# WKUP_CTRL_MMR0 register map
Vendor: Texas Instruments
Peripheral module from a debugger description file (folder J7ES).
Registers are 32-bit, access per field, reset 0x0 unless marked. A register's access mark holds for its fields unless they carry their own. Offsets are as the file gives them; lines under a group give offsets from that group; [hi:lo] are bit positions; {n}, {i} and the like mark numbered series; 'fields as' and 'values as' point back to an identical list; <NAME> marks a mode.

## WKUP_CTRL_MMR0
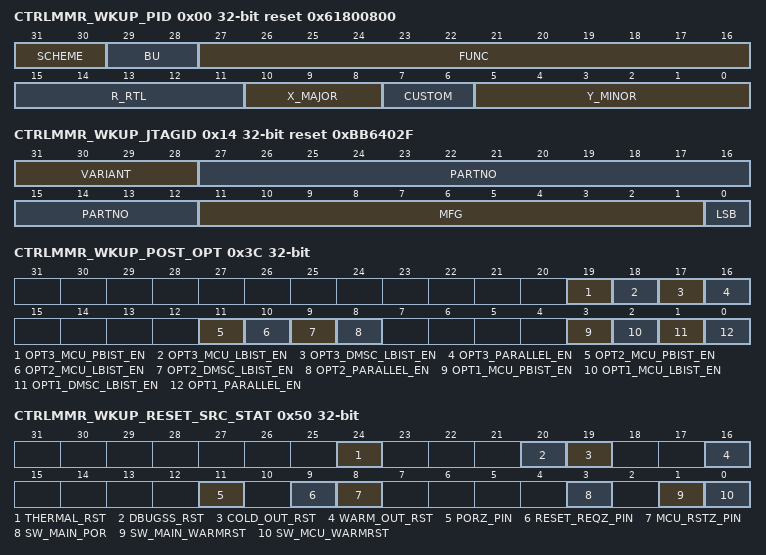
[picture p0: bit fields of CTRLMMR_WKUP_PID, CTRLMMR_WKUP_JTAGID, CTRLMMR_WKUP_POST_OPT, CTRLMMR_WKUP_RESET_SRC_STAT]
0x00 CTRLMMR_WKUP_PID ro reset 0x61800800 — Peripheral release details.
  [31:30] SCHEME
  [29:28] BU — Business unit
  [27:16] FUNC — Module functional identifier
  [15:11] R_RTL — RTL revision
  [10:8] X_MAJOR — Major revision
  [7:6] CUSTOM — Custom revision
  [5:0] Y_MINOR — Minor revision
0x08 CTRLMMR_WKUP_MMR_CFG1 ro reset 0x800000DF — Indicates the MMR configuration.
  [7:0] PARTITIONS — Indicates present partitions
0x14 CTRLMMR_WKUP_JTAGID ro reset 0xBB6402F — The register must be readable by the configuration bus so that this can be accessed via the JTAG and CPU. In Boundary Scan mode, this ID should also be readable with only TCLK present. This means without a valid CPU clock running and also implies that Fusefarm scan is not necessary. The Variant field should be set in the top metal mask so that this may be changed if a future PG is necessary. All other fields may be hard coded.
  [31:28] VARIANT — Used to indicate new PGs
  [27:12] PARTNO — Part number for boundary scan
  [11:1] MFG — Indicates manufacturer
  [0] LSB — Always 1
{0x20+4i} CTRLMMR_WKUP_DIE_ID{i} ro reset not defined (i=0..3) — Contains information to identify this particular die.
  [31:0] DIEID — Contains individual die information
0x30 CTRLMMR_WKUP_DEVSTAT (reset mask 0xFFFFFC00) — Indicates MCU bootstrap selection. The default value of this register is determined by the MCU bootstrap pins when the por_boot_cfg_srst_n input is de-asserted.
  [9:0] BOOTMODE rw — Indicates MCU bootstrap selection. The default value of this register is determined by the MCU bootstrap pins when the por_boot_cfg_srst_n input is de-asserted. However, this register can be written before a warm boot to invoke a different boot mode than that latched from the BOOTMODE pins.
0x34 CTRLMMR_WKUP_BOOTCFG ro (reset mask 0xFFFFFC00) — Indicates MCU bootstrap selection latched at power-on reset by PORz. The default value of this register is determined by the MCU bootstrap pins when the por_boot_cfg_srst_n input is de-asserted and will remain until the MCU bootstrap pins are re-latched on a subsequent por_boot_cfg_srst_n rising edge.
  [9:0] BOOTMODE — Indicates MCU boot mode as latched at power-on reset. These bits always contain the values latched.
0x38 CTRLMMR_WKUP_POST_SEL_STAT ro (reset mask 0xFFFFFFFC) — Indicates which power-on self test option was performed.
  [1:0] POST_SEL_STAT — Indicates which POST option was selected at power-up
0x3C CTRLMMR_WKUP_POST_OPT ro (reset mask 0xFFF0F0F0) — Indicates the 3 available power-on self test (POST) options: Bits 3:0 - POST Option 1 Bits 11:8 - POST Option 2 Bits 19:16 - POST Option 3
  [19] OPT3_MCU_PBIST_EN — MCU R5 PBIST enabled
  [18] OPT3_MCU_LBIST_EN — MCU R5 LBIST enabled
  [17] OPT3_DMSC_LBIST_EN — DMSC LBIST enabled
  [16] OPT3_PARALLEL_EN — Selects DMSC/MCU R5 LBIST sequencing
  [11] OPT2_MCU_PBIST_EN — MCU R5 PBIST enabled
  [10] OPT2_MCU_LBIST_EN — MCU R5 LBIST enabled
  [9] OPT2_DMSC_LBIST_EN — DMSC LBIST enabled
  [8] OPT2_PARALLEL_EN — Selects DMSC/MCU R5 LBIST sequencing
  [3] OPT1_MCU_PBIST_EN — MCU R5 PBIST enabled
  [2] OPT1_MCU_LBIST_EN — MCU R5 LBIST enabled
  [1] OPT1_DMSC_LBIST_EN — DMSC LBIST enabled
  [0] OPT1_PARALLEL_EN — Selects DMSC/MCU R5 LBIST sequencing
0x50 CTRLMMR_WKUP_RESET_SRC_STAT access not given — Indicates source of last device reset.
  [24] THERMAL_RST — When set, indicates that a VTM Max Temp Thermal reset occurred. (access REC)
  [20] DBUGSS_RST — When set, indicates that a Debug reset occurred. (access FEC)
  [19] COLD_OUT_RST — When set, indicates that a DMSC Cold reset occurred. (access FEC)
  [16] WARM_OUT_RST — When set, indicates that a DSMC Warm reset occured. (access FEC)
  [11] PORZ_PIN — When set indicates that a PORz pin reset occurred. (access FEC)
  [9] RESET_REQZ_PIN — When set indicates that a RESET_REQz pin reset occurred. (access FEC)
  [8] MCU_RSTZ_PIN — When set indicates that a MCU_RESETz pin reset occurred. (access FEC)
  [3] SW_MAIN_POR — When set, indicates that a Software MAIN Power-on reset occurred. (access FEC)
  [1] SW_MAIN_WARMRST — When set indicates that a Software MAIN Warm reset occurred. (access FEC)
  [0] SW_MCU_WARMRST — When set indicates that a Software MCU Warm reset occurred. (access FEC)
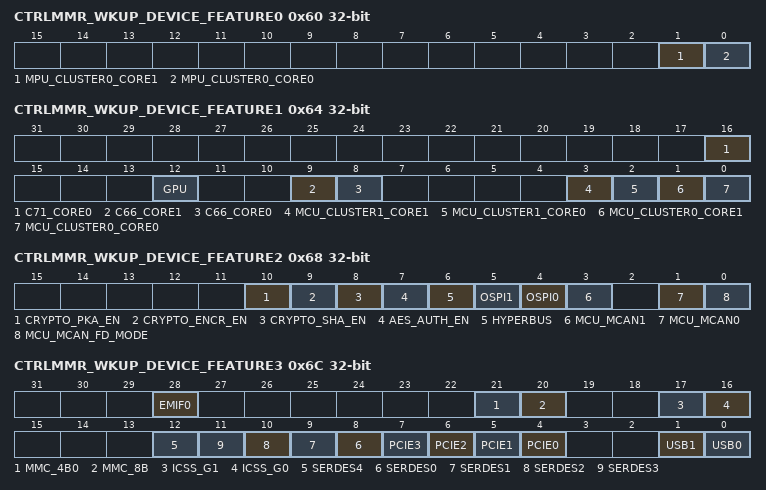
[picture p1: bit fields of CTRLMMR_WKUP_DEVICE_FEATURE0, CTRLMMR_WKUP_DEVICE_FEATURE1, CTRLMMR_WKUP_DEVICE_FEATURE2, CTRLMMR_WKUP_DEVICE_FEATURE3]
0x60 CTRLMMR_WKUP_DEVICE_FEATURE0 ro (reset mask 0xFFFFFFCC) — Indicates enabled MPU processing elements on the device.
  [1] MPU_CLUSTER0_CORE1 — MPU Cluster0 Core 1 is enabled when set
  [0] MPU_CLUSTER0_CORE0 — MPU Cluster0 Core 0 is enabled when set
0x64 CTRLMMR_WKUP_DEVICE_FEATURE1 ro (reset mask 0xFFFCECF0) — Indicates enabled non-MPU processing elements on the device.
  [16] C71_CORE0 — C71 Core0 is enabled when set
  [12] GPU — GPU is enabled when set
  [9] C66_CORE1 — C66 Core1 is enabled when set
  [8] C66_CORE0 — C66 Core0 is enabled when set
  [3] MCU_CLUSTER1_CORE1 — MAIN MCU Cluster1 Core1 is enabled when set
  [2] MCU_CLUSTER1_CORE0 — MAIN MCU Cluster1 Core0 is enabled when set
  [1] MCU_CLUSTER0_CORE1 — MAIN MCU Cluster0 Core1 is enabled when set
  [0] MCU_CLUSTER0_CORE0 — MAIN MCU Cluster0 Core0 is enabled when set
0x68 CTRLMMR_WKUP_DEVICE_FEATURE2 ro (reset mask 0xFFFFF804) — Indicates enabled MCU domain interface elements on the device.
  [10] CRYPTO_PKA_EN — MCU SA2_UL Crypto Module PKA enabled
  [9] CRYPTO_ENCR_EN — MCU SA2_UL Crypto Module AES/3DES/DBRG enabled
  [8] CRYPTO_SHA_EN — MCU SA2_UL Crypto Module SHA/MD5 enabled
  [7] AES_AUTH_EN — AES authentication is enabled in MCU_FlashSS and DMSC when set
  [6] HYPERBUS — MCU_FSS0_HPB0 is enabled when set
  [5] OSPI1 — MCU_OSPI1 is enabled when set
  [4] OSPI0 — MCU_OSPI0 is enabled when set
  [3] MCU_MCAN1 — MCU_MCAN1 is enabled when set
  [1] MCU_MCAN0 — MCU_MCAN0 is enabled when set
  [0] MCU_MCAN_FD_MODE — FD mode is supported on MCU_MCAN[1:0] when set
0x6C CTRLMMR_WKUP_DEVICE_FEATURE3 ro (reset mask 0xCF8CC008) — Indicates enabled MAIN domain interface elements on the device.
  [28] EMIF0 — EMIF0 is enabled when set
  [21] MMC_4B0 — 4-bit MMCSD1 is enabled when set
  [20] MMC_8B — 8-bit MMCSD0 is enabled when set
  [17] ICSS_G1 — ICSS_G1 is enabled when set
  [16] ICSS_G0 — ICSS_G0 is enabled when set
  [12] SERDES4 — 10G SERDES4 is enabled when set
  [n+8] SERDES{n} (n=0..3) — 16G SERDES{n} is enabled when set
  [n+4] PCIE{n} (n=0..3) — PCIe{n} is enabled when set
  [1] USB1 — USB1 is enabled when set
  [0] USB0 — USB0 is enabled when set
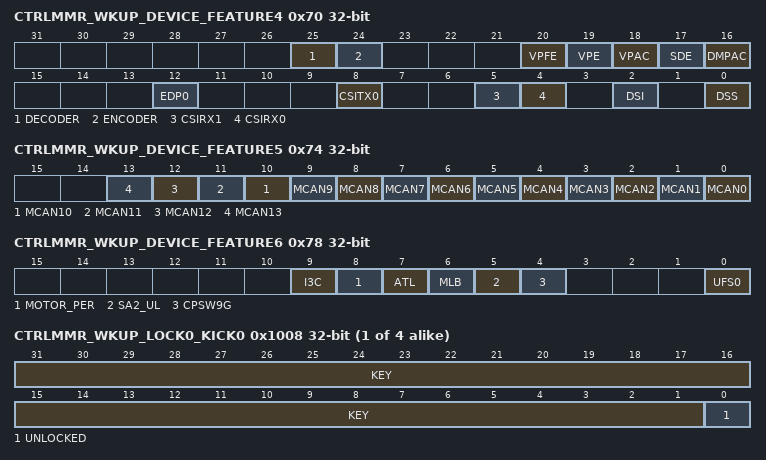
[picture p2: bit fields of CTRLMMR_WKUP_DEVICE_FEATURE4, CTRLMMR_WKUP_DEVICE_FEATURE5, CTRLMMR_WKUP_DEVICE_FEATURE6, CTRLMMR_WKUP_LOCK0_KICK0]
0x70 CTRLMMR_WKUP_DEVICE_FEATURE4 ro (reset mask 0xFCE0CE8A) — Indicates enabled MAIN domain interface elements on the device.
  [25] DECODER — Video decoder is enabled when set
  [24] ENCODER — Video encoder is enabled when set
  [20] VPFE — VPFE is enabled when set
  [19] VPE — Video processing engine is enabled when set
  [18] VPAC — VPAC is enabled when set
  [17] SDE — DMPAC Stereo Disparity Engine is enabled when set
  [16] DMPAC — DMPAC is enabled when set
  [12] EDP0 — Embedded display port 0 is enabled when set
  [8] CSITX0 — CSI_TX0 is enabled when set
  [5] CSIRX1 — CSI_RX1 is enabled when set
  [4] CSIRX0 — CSI_RX0 is enabled when set
  [2] DSI — DSI is enabled when set
  [0] DSS — DSS is enabled when set
0x74 CTRLMMR_WKUP_DEVICE_FEATURE5 ro (reset mask 0xFFFFC000) — Indicates enabled MAIN domain interface elements on the device.
  [n] MCAN{n} (n=0..13) — MCAN{n} is enabled when set
0x78 CTRLMMR_WKUP_DEVICE_FEATURE6 ro (reset mask 0xFF8CFC0C) — Indicates enabled MAIN domain interface elements on the device.
  [9] I3C — MAIN domain I3C is enabled when set
  [8] MOTOR_PER — Motor control peripherals (eCAP, eQEP, eHRPWM) are enabled when set
  [7] ATL — Audio tracking logic is enabled when set
  [6] MLB — Media local bus is enabled when set
  [5] SA2_UL — MAIN domain security accelerator is enabled when set
  [4] CPSW9G — 8 Channel Q/SGMII Ethernet switch enabled when set
  [0] UFS0 — UFS interface 0 is enabled when set
{0x1008+0x4000*i} CTRLMMR_WKUP_LOCK{i}_KICK0 (i=0..3) — Lower 32-bits of Partition{i} write lock key. This register must be written with the designated key value followed by a write to with its key value before write-protected Partition {i} registers can be written.
  [31:1] KEY rw — Write the kick0 unlock value followed by the kick1 unlock value to unlock the write-protected Partition{i} registers
  [0] UNLOCKED ro — Unlock status.
{0x100C+0x4000*i} CTRLMMR_WKUP_LOCK{i}_KICK1 rw (i=0..3) — Upper 32-bits of Partition {i} write lock key. This register must be written with the designated key value after a write to with its key value before write-protected Partition {i} registers can be written.
  [31:0] KEY — Write the kick1 unlock value after the kick0 unlock value to unlock the write-protected Partition{i} registers
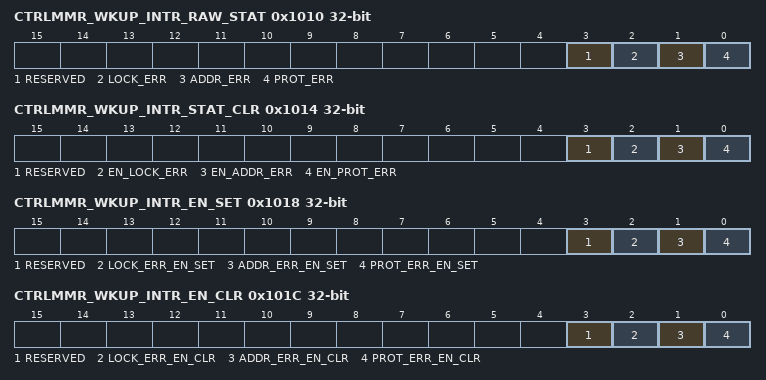
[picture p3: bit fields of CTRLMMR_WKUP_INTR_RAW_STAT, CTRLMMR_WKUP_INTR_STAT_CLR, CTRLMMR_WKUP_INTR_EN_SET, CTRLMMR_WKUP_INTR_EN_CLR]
0x1010 CTRLMMR_WKUP_INTR_RAW_STAT access not given — Shows the interrupt status (before enabling) and allows setting of the interrupt status (for test).
  [3] RESERVED — (access W1TS)
  [2] LOCK_ERR — Lock violation occurred (attempt to write a write-locked register with partition locked) (access W1TS)
  [1] ADDR_ERR — Address violation occurred (attempt to read or write an invalid register address) (access W1TS)
  [0] PROT_ERR — Protection violation occurred (attempt to read or write a register with insufficient security or privilege access rights) (access W1TS)
0x1014 CTRLMMR_WKUP_INTR_STAT_CLR access not given — Shows the enabled interrupt status and allows the interrupt to be cleared.
  [3] RESERVED — (access W1TC)
  [2] EN_LOCK_ERR — Enabled lock interrupt event status (access W1TC)
  [1] EN_ADDR_ERR — Enabled address interrupt event status (access W1TC)
  [0] EN_PROT_ERR — Enabled protection interrupt event status (access W1TC)
0x1018 CTRLMMR_WKUP_INTR_EN_SET access not given — Allows interrupt enables to be set.
  [3] RESERVED — (access W1TS)
  [2] LOCK_ERR_EN_SET — Lock interrupt enable (access W1TS)
  [1] ADDR_ERR_EN_SET — Address interrupt enable (access W1TS)
  [0] PROT_ERR_EN_SET — Protection interrupt enable (access W1TS)
0x101C CTRLMMR_WKUP_INTR_EN_CLR access not given — Allows interrupt enables to be cleared.
  [3] RESERVED — (access W1TC)
  [2] LOCK_ERR_EN_CLR — Lock interrupt disable (access W1TC)
  [1] ADDR_ERR_EN_CLR — Address interrupt disable (access W1TC)
  [0] PROT_ERR_EN_CLR — Protection interrupt disable (access W1TC)
0x1020 CTRLMMR_WKUP_EOI — EOI Vector value. This register should be written with interrupt distribution value required by the device architecture to indicate service completion of the MMR interrupt. The EOI register is used to re-trigger the pulse interrupt signal to ensure that any nested interrupt events are serviced. The software interrupt handler must write to the EOI register at the end of the current interrupt processing routine, so that new events can re-trigger the pulse interrupt signal again. For level interrupt signals the EOI register is not functional and must not be used.
  [7:0] VECTOR rw — EOI vector value
0x1024 CTRLMMR_WKUP_FAULT_ADDR ro — Indicates the address of the first transfer that caused a fault to occur.
  [31:0] ADDRESS — Address of the faulted access
0x1028 CTRLMMR_WKUP_FAULT_TYPE ro — Indicates the access type of the first transfer that caused a fault to occur.
  [5:0] TYPE — Type of access which faulted 0h - No fault 1h - User execute access 2h - User write access 4h - User read access 8h - Supervisor execute access 10h - Supervisor write access 20h - Supervisor read access
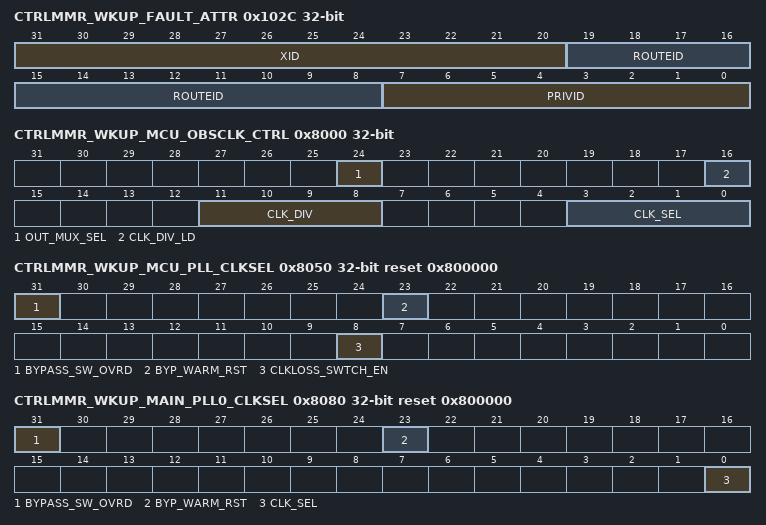
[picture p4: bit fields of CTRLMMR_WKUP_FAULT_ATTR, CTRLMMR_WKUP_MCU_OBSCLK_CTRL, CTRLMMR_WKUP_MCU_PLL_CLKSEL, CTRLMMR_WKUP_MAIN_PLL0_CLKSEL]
0x102C CTRLMMR_WKUP_FAULT_ATTR ro — Indicates the attributes of the first transfer that caused a fault to occur.
  [31:20] XID — Transaction ID
  [19:8] ROUTEID
  [7:0] PRIVID — Privilege ID
0x1030 CTRLMMR_WKUP_FAULT_CLR access not given — Allows software to clear the current fault. Clearing the current fault allows the , , and registers to latch the attributes of the next fault that occurs. This does not affect the fault interrupt event itself. The interrupt must be cleared using the appropriate INTR_STATUS_CLR register bits.
  [0] CLEAR — Fault clear (access W1TC)
0x4004 CTRLMMR_WKUP_MAIN_PWR_CTRL reset 0x1 — Controls power options for the MAIN voltage domain.
  [0] PWR_EN rw — When set, drives the PMIC_POWER_EN1 output pin causing PMIC to turn on the MAIN voltage domain
0x4020 CTRLMMR_WKUP_GPIO_CTRL — Controls operation of the WKUP_GPIO module.
  [0] WAKEN rw — Enables WKUP_GPIO wakeup event operation by controling the WKUP_GPIO LPSC clockstop_ack behavior. 0h - No WKUP_GPIO wakeup support. WKUP_GPIO vbus clock is gated on clkstop_ack from WKUP_GPIO to LPSC 1h - WKUP_GPIO wakeup enabled. WKUP_GPIO vbus clock is NOT gated on LPSC clockstop_req. WKUP_GPIO LPSC clkstop_ack input is driven by clkstop_req output.
0x4030 CTRLMMR_WKUP_I2C0_CTRL — Controls WKUP_I2C0 operation.
  [0] HS_MCS_EN rw — HS Mode master current source enable.
{0x4080+4i} CTRLMMR_WKUP_DBOUNCE_CFG{i} (i=1..6) — Configures IO debounce selections.
  [5:0] DB_CFG rw — Configures the debounce period used for I/Os with DEBOUNCE_SEL set to {i}h.
0x8000 CTRLMMR_WKUP_MCU_OBSCLK_CTRL — Controls which internal clock is made observable on the MCU_OBSCLK output pin.
  [24] OUT_MUX_SEL rw — MCU_OBSCLK pin output mux selection.
  [16] CLK_DIV_LD rw — Load the output divider value
  [11:8] CLK_DIV rw — MCU_OBSCLK pin clock selection output divider
  [3:0] CLK_SEL rw — MCU_OBSCLK pin clock selection 0h - CLK_12M_RC 1h - '0' 2h - MCU_PLL0_HSDIV0_CLKOUT 3h - MCU_PLLCTL_OBSCLK 4h - MCU_PLL1_HSDIV1_CLKOUT 5h - MCU_PLL1_HSDIV2_CLKOUT 6h - MCU_PLL1_HSDIV3_CLKOUT 7h - MCU_PLL1_HSDIV4_CLKOUT 8h - MCU_PLL2_HSDIV0_CLKOUT 9h - CLK_32K Ah - MCU_PLL2_HSDIV1_CLKOUT Bh - MCU_PLL2_HSDIV2_CLKOUT Ch - MCU_PLL2_HSDIV3_CLKOUT Dh - MCU_PLL2_HSDIV4_CLKOUT Eh - WKUP_HFOSC0_CLKOUT Fh - WKUP_LFOSC0_CLKOUT
0x8030 CTRLMMR_WKUP_LFXOSC_CTRL reset 0x80 — Controls the operation of the low frequency oscillator.
  [7] PD_C rw — Oscillator powerdown control. When set, oscillator is disabled.
0x8034 CTRLMMR_WKUP_LFXOSC_TRIM (reset mask 0xFFC8C000) — Provides frequency trimming for the low frequency oscillator module.
  [18:16] I_MULT rw — AGC AMP current multiplication gain 0h - 3x AMP_AGC IBIAS 1h - 4x AMP_AGC IBIAS 2h - 5x AMP_AGC IBIAS 3h - 6x AMP_AGC IBIAS 4h - 7x AMP_AGC IBIAS 5h - 8x AMP_AGC IBIAS 6h - 9x AMP_AGC IBIAS 7h - 10x AMP_AGC IBIAS
0x8050 CTRLMMR_WKUP_MCU_PLL_CLKSEL reset 0x800000 — Controls the clock source for MCU voltage domain PLL[2:0].
  [31] BYPASS_SW_OVRD rw — PLL Bypass warm reset software override
  [23] BYP_WARM_RST rw — PLL bypass mode after warm reset.
  [8] CLKLOSS_SWTCH_EN rw — When set, enables automatic switching of MCU PLL[2:0] clock source to CLK_12M_RC if WKUP_HFOSC0 clock loss is detected
0x8060 CTRLMMR_WKUP_PER_CLKSEL — Controls the wakeup peripheral functional clock source. Allows the main oscillator to be used as the functional clock source for the WKUP_USART and WKUP_I2C when PLLs are powered down.
  [0] MCUPLL_BYPASS rw — Select the main oscillator clock rather than the PLL generated clock as the functional clock (PLL BYPASS mode).
0x8064 CTRLMMR_WKUP_USART_CLKSEL — Controls the functional clock source for WKUP_USART0.
  [0] CLK_SEL rw — WKUP_USART0 FCLK selection
0x8070 CTRLMMR_WKUP_GPIO_CLKSEL — Controls the functional clock source for WKUP_GPIO.
  [1:0] WAKE_CLK_SEL rw — WKUP_GPIO clock selection. Must be set to MCU_SYSCLK0/6 whenever WKUP_GPIO VBUS interface is enabled. Other clock source may be selected as a wake up clock for DeepSleep modes after WKUP_GPIO is gated off through LPSC. 0h - MCU_SYSCLK0 / 6 1h - MCU_SYSCLK0 / 6 2h - CLK_32K 3h - CLK_12M_RC
0x8080 CTRLMMR_WKUP_MAIN_PLL0_CLKSEL reset 0x800000 — Controls the clock source for MAIN voltage domain PLL0.
  [31] BYPASS_SW_OVRD rw — PLL Bypass warm reset software override
  [23] BYP_WARM_RST rw — PLL bypass mode after warm reset.
  [0] CLK_SEL rw — Selects the clock source for MAIN PLL0
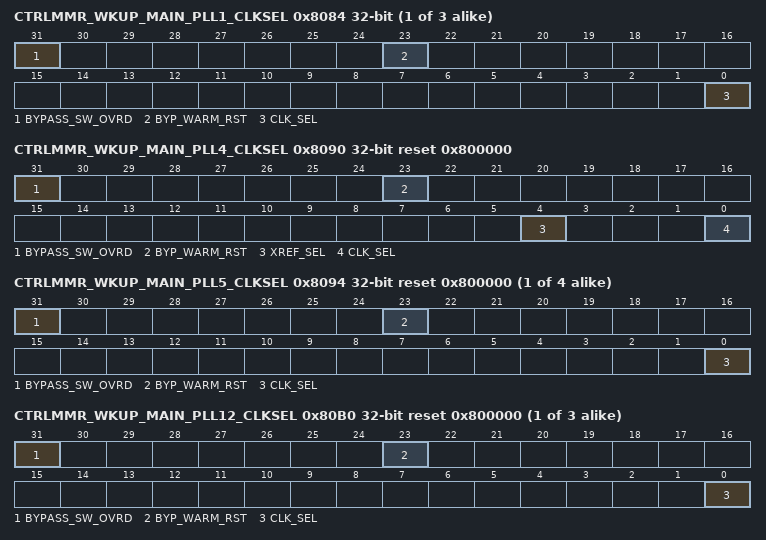
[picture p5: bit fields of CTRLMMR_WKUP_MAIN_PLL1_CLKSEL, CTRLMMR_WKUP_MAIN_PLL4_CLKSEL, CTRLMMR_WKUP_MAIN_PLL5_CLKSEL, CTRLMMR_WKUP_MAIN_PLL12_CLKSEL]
{0x8080+4i} CTRLMMR_WKUP_MAIN_PLL{i}_CLKSEL (i=1..3) — Controls the clock source for MAIN voltage domain PLL{i}.
  [31] BYPASS_SW_OVRD rw — PLL Bypass warm reset software override
  [23] BYP_WARM_RST rw — PLL bypass mode after warm reset.
  [0] CLK_SEL rw — Selects the clock source for MAIN PLL{i}
0x8090 CTRLMMR_WKUP_MAIN_PLL4_CLKSEL reset 0x800000 — Controls the clock source for MAIN voltage domain PLL4.
  [31] BYPASS_SW_OVRD rw — PLL Bypass warm reset software override
  [23] BYP_WARM_RST rw — PLL bypass mode after warm reset.
  [4] XREF_SEL rw — Selects the alternate clock source for MAIN PLL4
  [0] CLK_SEL rw — Selects the clock source for MAIN PLL4
{0x8080+4i} CTRLMMR_WKUP_MAIN_PLL{i}_CLKSEL reset 0x800000 (i=5..8) — Controls the clock source for MAIN voltage domain PLL{i}.
  fields as CTRLMMR_WKUP_MAIN_PLL1_CLKSEL
{0x8080+4i} CTRLMMR_WKUP_MAIN_PLL{i}_CLKSEL reset 0x800000 (i=12..14) — Controls the clock source for MAIN voltage domain PLL{i}.
  fields as CTRLMMR_WKUP_MAIN_PLL1_CLKSEL
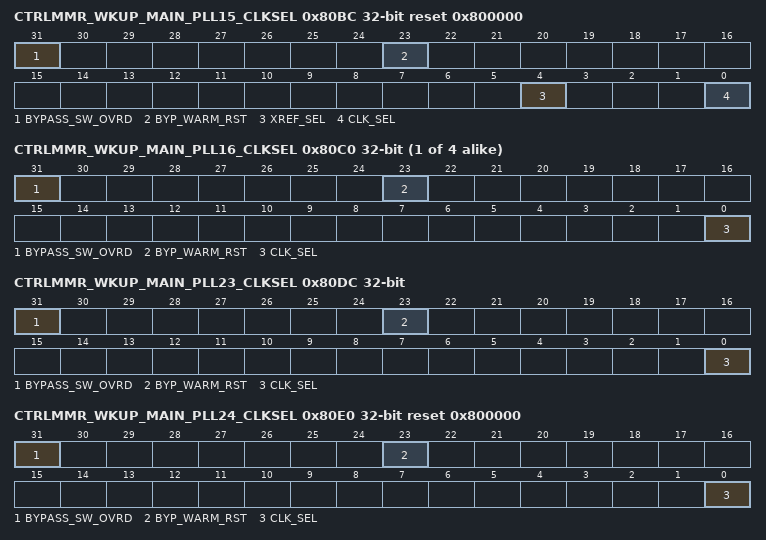
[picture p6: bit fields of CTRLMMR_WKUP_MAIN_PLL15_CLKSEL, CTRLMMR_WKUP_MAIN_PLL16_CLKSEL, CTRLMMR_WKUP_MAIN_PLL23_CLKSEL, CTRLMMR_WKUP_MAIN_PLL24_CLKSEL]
0x80BC CTRLMMR_WKUP_MAIN_PLL15_CLKSEL reset 0x800000 — Controls the clock source for MAIN voltage domain PLL15.
  [31] BYPASS_SW_OVRD rw — PLL Bypass warm reset software override
  [23] BYP_WARM_RST rw — PLL bypass mode after warm reset.
  [4] XREF_SEL rw — Selects the alternate clock source for MAIN PLL15
  [0] CLK_SEL rw — Selects the clock source for MAIN PLL15
{0x8080+4i} CTRLMMR_WKUP_MAIN_PLL{i}_CLKSEL (i=16..19) — Controls the clock source for MAIN voltage domain PLL{i}.
  fields as CTRLMMR_WKUP_MAIN_PLL1_CLKSEL
0x80DC CTRLMMR_WKUP_MAIN_PLL23_CLKSEL — Controls the clock source for MAIN voltage domain PLL23.
  [31] BYPASS_SW_OVRD rw — PLL Bypass warm reset software override
  [23] BYP_WARM_RST rw — PLL bypass mode after warm reset.
  [0] CLK_SEL rw — Selects the clock source for MAIN PLL23
0x80E0 CTRLMMR_WKUP_MAIN_PLL24_CLKSEL reset 0x800000 — Controls the clock source for MAIN voltage domain PLL24.
  [31] BYPASS_SW_OVRD rw — PLL Bypass warm reset software override
  [23] BYP_WARM_RST rw — PLL bypass mode after warm reset.
  [0] CLK_SEL rw — Selects the clock source for MAIN PLL24
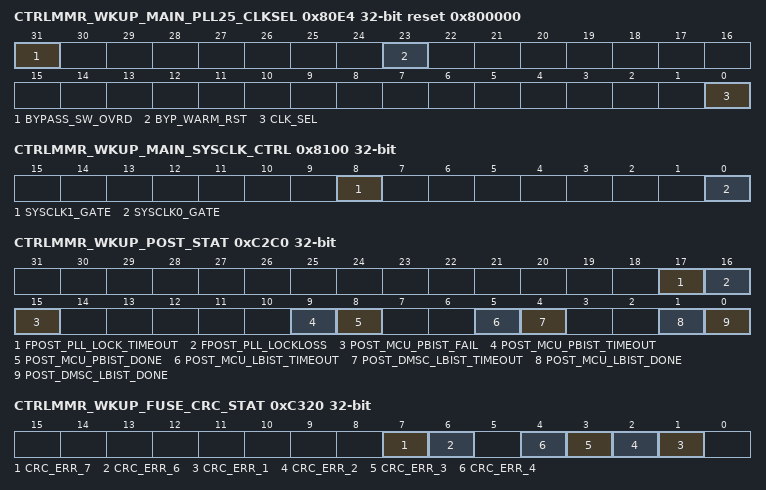
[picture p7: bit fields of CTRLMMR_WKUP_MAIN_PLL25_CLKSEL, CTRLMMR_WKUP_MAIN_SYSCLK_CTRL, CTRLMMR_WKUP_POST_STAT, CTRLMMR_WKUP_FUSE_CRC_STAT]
0x80E4 CTRLMMR_WKUP_MAIN_PLL25_CLKSEL reset 0x800000 — Controls the clock source for MAIN voltage domain PLL25.
  [31] BYPASS_SW_OVRD rw — PLL Bypass warm reset software override
  [23] BYP_WARM_RST rw — PLL bypass mode after warm reset.
  [0] CLK_SEL rw — Selects the clock source for MAIN PLL25
0x8100 CTRLMMR_WKUP_MAIN_SYSCLK_CTRL — Controls clock gating of the MAIN PLL Controller SYSCLK outputs.
  [8] SYSCLK1_GATE rw — When set, gates off SYSCLK1 output of the MAIN PLL Controller
  [0] SYSCLK0_GATE rw — When set, gates off SYSCLK0 (MCLK1) output of the MAIN PLL Controller
0x8110 CTRLMMR_WKUP_MCU_SPI0_CLKSEL — MCU_SPI0 clock control.
  [16] MSTR_LB_CLKSEL rw — Master mode receive capture clock loopback selection
0x8114 CTRLMMR_WKUP_MCU_SPI1_CLKSEL — MCU_SPI1 clock control.
  fields as CTRLMMR_WKUP_MCU_SPI0_CLKSEL
0xC280 CTRLMMR_WKUP_DMSC_LBIST_SIG ro reset not defined — Contains expected MISR output value.
  [31:0] MISR_SIG — MISR signature
0xC2C0 CTRLMMR_WKUP_POST_STAT ro (reset mask 0xFFFC7CCC) — Contains the result of power-on self tests.
  [17] FPOST_PLL_LOCK_TIMEOUT — Indicates PLL lock timeout for Fast POST mode operation.
  [16] FPOST_PLL_LOCKLOSS — Indicates if PLL lock was lost during POST
  [15] POST_MCU_PBIST_FAIL — MCU PBIST failed
  [9] POST_MCU_PBIST_TIMEOUT — MCU PBIST timed out
  [8] POST_MCU_PBIST_DONE — MCU PBIST done
  [5] POST_MCU_LBIST_TIMEOUT — MCU LBIST timed out
  [4] POST_DMSC_LBIST_TIMEOUT — DMSC LBIST timed out
  [1] POST_MCU_LBIST_DONE — MCU LBIST done
  [0] POST_DMSC_LBIST_DONE — DMSC LBIST done
0xC320 CTRLMMR_WKUP_FUSE_CRC_STAT ro (reset mask 0xFFFFFF21) — Indicates status of fuse chain CRC.
  [7] CRC_ERR_7 — Indicates eFuse CRC error on chain 7
  [6] CRC_ERR_6 — Indicates eFuse CRC error on chain 6
  [n] CRC_ERR_{n} (n=1..4) — Indicates eFuse CRC error on chain {n}
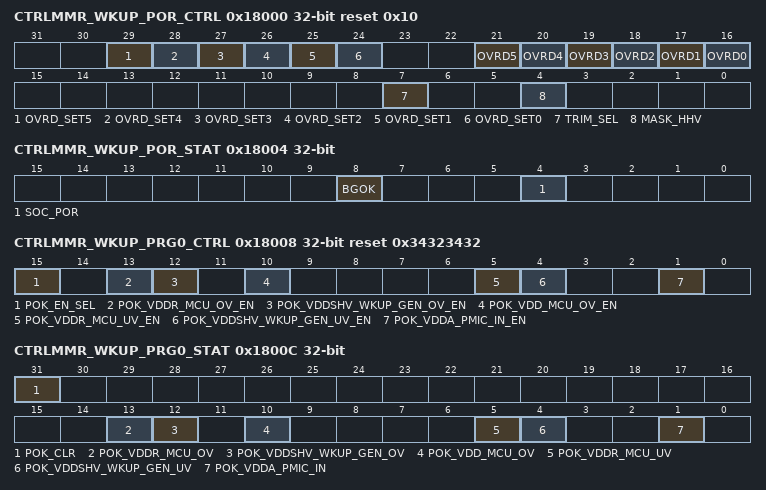
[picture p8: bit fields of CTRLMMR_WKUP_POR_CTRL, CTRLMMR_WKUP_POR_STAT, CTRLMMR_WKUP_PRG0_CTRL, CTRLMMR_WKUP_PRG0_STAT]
0x18000 CTRLMMR_WKUP_POR_CTRL reset 0x10 — Configures POR module reset behavior.
  [29] OVRD_SET5 rw — Reserved override set
  [28] OVRD_SET4 rw — POKLVB override set
  [27] OVRD_SET3 rw — POKLVA override set
  [26] OVRD_SET2 rw — POKHV override set
  [25] OVRD_SET1 rw — BGOK override set
  [24] OVRD_SET0 rw — PORHV override set
  [21] OVRD5 rw — Reserved override enable
  [20] OVRD4 rw — POKLVB override enable
  [19] OVRD3 rw — POKLVA override enable
  [18] OVRD2 rw — POKHV override enable
  [17] OVRD1 rw — BGOK override enable
  [16] OVRD0 rw — PORHV override enable
  [7] TRIM_SEL rw — POR Trim Select
  [4] MASK_HHV rw — Mask HHV/SOC_PORz outputs when applying new trim values
0x18004 CTRLMMR_WKUP_POR_STAT ro (reset mask 0xFFFFFEEF) — Shows POR module status.
  [8] BGOK — Bandgap OK status
  [4] SOC_POR — POR module status
0x18008 CTRLMMR_WKUP_PRG0_CTRL reset 0x34323432 — Configures the WKUP domain PRG0 controller.
  [15] POK_EN_SEL rw — Select POK enable source
  [13] POK_VDDR_MCU_OV_EN rw — Enable VDDR_MCU overvoltage POK detection
  [12] POK_VDDSHV_WKUP_GEN_OV_EN rw — Enable VDDSHV_WKUP_GENERAL overvoltage POK detection
  [10] POK_VDD_MCU_OV_EN rw — Enable VDD_MCU overvoltage POK detection
  [5] POK_VDDR_MCU_UV_EN rw — Enable VDDR_MCU undervoltage POK detection
  [4] POK_VDDSHV_WKUP_GEN_UV_EN rw — Enable VDDSHV_WKUP_GENERAL undervoltage POK detection
  [1] POK_VDDA_PMIC_IN_EN rw — Enable VDDA_PMIC_IN POK detection
0x1800C CTRLMMR_WKUP_PRG0_STAT (reset mask 0xFFFFCBCD) — Provides WKUP domain PRG0 controller status and status clear control.
  [31] POK_CLR rw — When set, resets pgood sticky bits for VDDA_PMIC_IN, VDDR_MCU, VDDSHV_WKUP_GENERAL, and VDD_MCU_OV voltage POK detection.
  [13] POK_VDDR_MCU_OV ro — VDDR_MCU overvoltage POK
  [12] POK_VDDSHV_WKUP_GEN_OV ro — VDDSHV_WKUP_GENERAL overvoltage POK
  [10] POK_VDD_MCU_OV ro — VDD_MCU overvoltage POK
  [5] POK_VDDR_MCU_UV ro — VDDR_MCU undervoltage POK
  [4] POK_VDDSHV_WKUP_GEN_UV ro — VDDSHV_WKUP_GENERAL undervoltage POK
  [1] POK_VDDA_PMIC_IN ro — VDDA_PMIC_IN POK
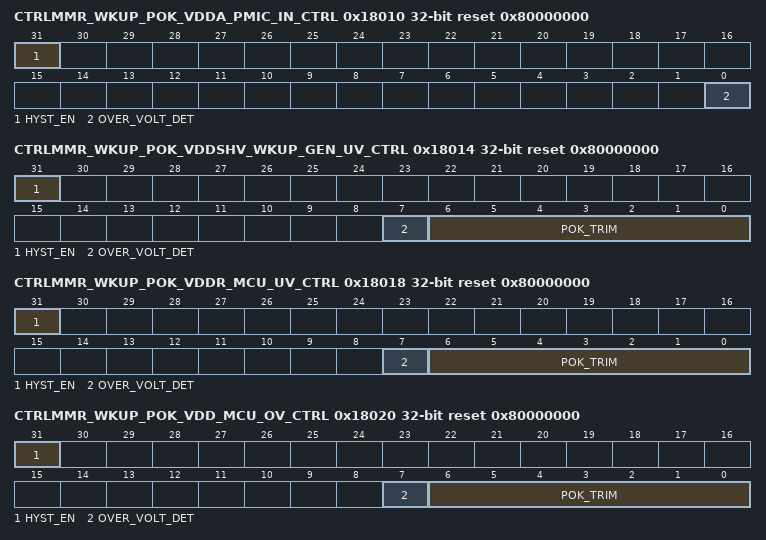
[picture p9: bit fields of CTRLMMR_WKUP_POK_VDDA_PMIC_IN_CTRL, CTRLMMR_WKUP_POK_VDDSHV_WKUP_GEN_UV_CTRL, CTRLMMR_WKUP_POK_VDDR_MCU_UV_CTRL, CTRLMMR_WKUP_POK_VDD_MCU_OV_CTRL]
0x18010 CTRLMMR_WKUP_POK_VDDA_PMIC_IN_CTRL reset 0x80000000 — Controls operation of the VDDA_PMIC_IN POK module.
  [31] HYST_EN rw — Enable POK hysteresis
  [0] OVER_VOLT_DET rw — Over / under voltage detection mode
0x18014 CTRLMMR_WKUP_POK_VDDSHV_WKUP_GEN_UV_CTRL reset 0x80000000 (reset mask 0xFFFFFF00) — Controls operation of the VDDSHV_WKUP_GENERAL undervoltage POK module.
  [31] HYST_EN rw — Enable POK hysteresis
  [7] OVER_VOLT_DET rw — Over / under voltage detection mode
  [6:0] POK_TRIM rw — POK trim bits. These bits are used to trim the comparator threshold voltage.
0x18018 CTRLMMR_WKUP_POK_VDDR_MCU_UV_CTRL reset 0x80000000 (reset mask 0xFFFFFF00) — Controls operation of the VDDR_MCU undervoltage POK module.
  fields as CTRLMMR_WKUP_POK_VDDSHV_WKUP_GEN_UV_CTRL
0x18020 CTRLMMR_WKUP_POK_VDD_MCU_OV_CTRL reset 0x80000000 (reset mask 0xFFFFFF00) — Controls operation of the VDD_MCU overvoltage POK module.
  fields as CTRLMMR_WKUP_POK_VDDSHV_WKUP_GEN_UV_CTRL
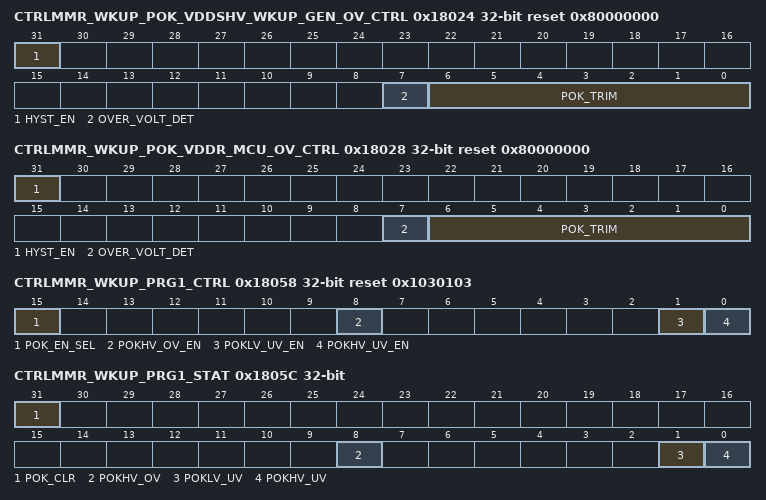
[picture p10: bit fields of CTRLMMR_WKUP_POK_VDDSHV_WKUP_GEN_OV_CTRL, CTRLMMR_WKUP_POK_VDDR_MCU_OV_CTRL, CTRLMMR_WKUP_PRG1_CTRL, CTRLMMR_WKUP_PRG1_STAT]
0x18024 CTRLMMR_WKUP_POK_VDDSHV_WKUP_GEN_OV_CTRL reset 0x80000000 (reset mask 0xFFFFFF00) — Controls operation of the VDDSHV_WKUP_GENERAL overvoltage POK module.
  fields as CTRLMMR_WKUP_POK_VDDSHV_WKUP_GEN_UV_CTRL
0x18028 CTRLMMR_WKUP_POK_VDDR_MCU_OV_CTRL reset 0x80000000 (reset mask 0xFFFFFF00) — Controls operation of the VDDR_MCU overvoltage POK module.
  fields as CTRLMMR_WKUP_POK_VDDSHV_WKUP_GEN_UV_CTRL
0x18058 CTRLMMR_WKUP_PRG1_CTRL reset 0x1030103 — Configures the WKUP domain PRG1 controller.
  [15] POK_EN_SEL rw — Select POK enable source
  [8] POKHV_OV_EN rw — Enable 1.8V VDDA_MCU overvoltage POK detection
  [1] POKLV_UV_EN rw — Enable VDD_MCU undervoltage POK detection
  [0] POKHV_UV_EN rw — Enable 1.8V VDDA_MCU undervoltage POK detection
0x1805C CTRLMMR_WKUP_PRG1_STAT (reset mask 0xFFFFFEFC) — Provides WKUP domain PRG1 controller status and status clear control.
  [31] POK_CLR rw — When set, resets pgood sticky bits for 1.8V VDDA_MCU and VDD_MCU_UV voltage POK detection.
  [8] POKHV_OV ro — 1.8V VDDA_MCU overvoltage POK
  [1] POKLV_UV ro — VDD_MCU under voltage POK
  [0] POKHV_UV ro — 1.8V VDDA_MCU undervoltage POK
0x18070 CTRLMMR_WKUP_MAIN_VDOM_CTRL — Provides MAIN voltage domain isolation for deep sleep operation.
  [0] MAIN_VD_OFF rw — MAIN deep sleep isolation enable. This bit should be set prior to powering off the MAIN voltage domain to ensure proper signal isolation.
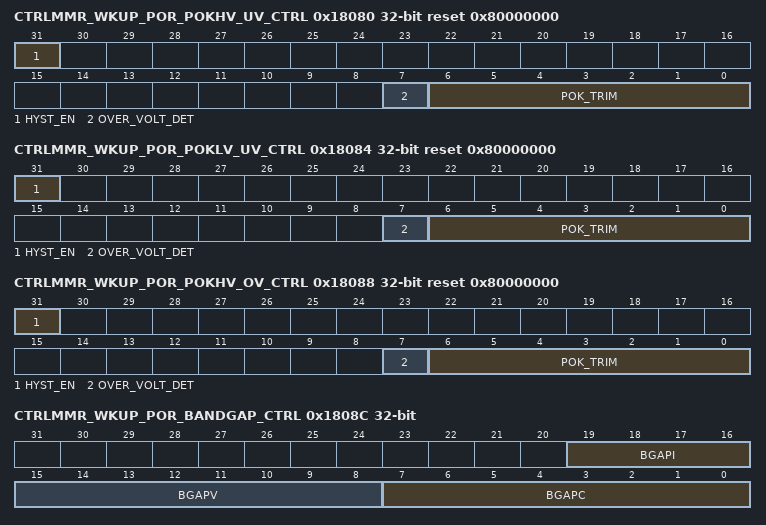
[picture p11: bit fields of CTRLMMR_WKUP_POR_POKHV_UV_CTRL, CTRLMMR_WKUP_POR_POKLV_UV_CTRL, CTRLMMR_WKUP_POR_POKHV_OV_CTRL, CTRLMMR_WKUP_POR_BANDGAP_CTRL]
0x18080 CTRLMMR_WKUP_POR_POKHV_UV_CTRL reset 0x80000000 (reset mask 0xFFFFFF00) — Controls operation of the 1.8V VDDA_MCU undervoltage POK within the POR.
  fields as CTRLMMR_WKUP_POK_VDDSHV_WKUP_GEN_UV_CTRL
0x18084 CTRLMMR_WKUP_POR_POKLV_UV_CTRL reset 0x80000000 (reset mask 0xFFFFFF00) — Controls operation of the VDD_MCU undervoltage POK within the POR.
  fields as CTRLMMR_WKUP_POK_VDDSHV_WKUP_GEN_UV_CTRL
0x18088 CTRLMMR_WKUP_POR_POKHV_OV_CTRL reset 0x80000000 (reset mask 0xFFFFFF00) — Controls operation of the 1.8V VDDA_MCU overvoltage POK within the POR.
  fields as CTRLMMR_WKUP_POK_VDDSHV_WKUP_GEN_UV_CTRL
0x1808C CTRLMMR_WKUP_POR_BANDGAP_CTRL (reset mask 0xFFF00000) — Controls the operation of the bandgap module within the POR.
  [19:16] BGAPI rw — Bandgap output current trim bits
  [15:8] BGAPV rw — Bandgap output voltage magnitude trim bits
  [7:0] BGAPC rw — Bandgap slope trim bits. Bit7 is used to calculate the offset
0x180A0 CTRLMMR_WKUP_TEMP_DIODE_TRIM (reset mask 0xFFFFC000) — Trims the silicon junction temperature diode calculation.
  [13:0] TRIM rw — Sets the diode non-ideality factor (n), starting from 100th place decimal and going down
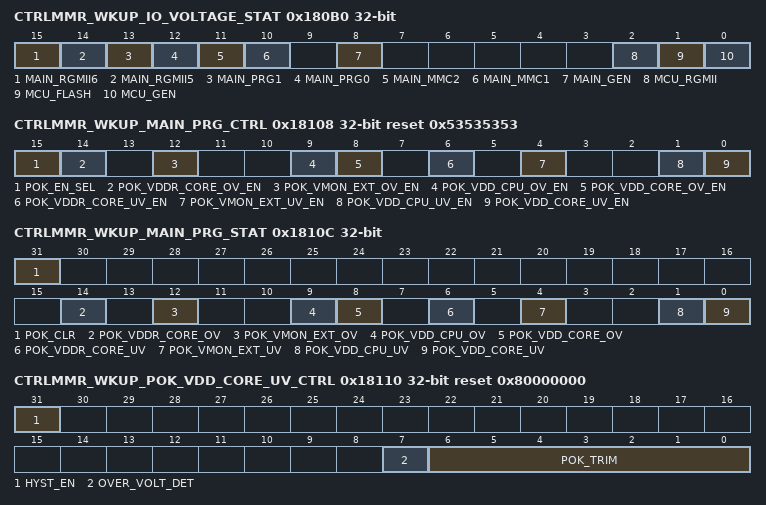
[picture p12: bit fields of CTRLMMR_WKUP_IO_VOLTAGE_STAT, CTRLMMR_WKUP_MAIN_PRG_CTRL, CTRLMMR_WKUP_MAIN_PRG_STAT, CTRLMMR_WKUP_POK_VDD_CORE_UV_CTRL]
0x180B0 CTRLMMR_WKUP_IO_VOLTAGE_STAT ro (reset mask 0xFFFF02F8) — Indicates the I/O voltage of each LVCMOS dual I/O group.
  [15] MAIN_RGMII6 — Indicates the voltage for the RGMII6 I/O group
  [14] MAIN_RGMII5 — Indicates the voltage for the RGMII5 I/O group
  [13] MAIN_PRG1 — Indicates the voltage for the PRG1 I/O group
  [12] MAIN_PRG0 — Indicates the voltage for the PRG0 I/O group
  [11] MAIN_MMC2 — Indicates the voltage for the MMC2 I/O group
  [10] MAIN_MMC1 — Indicates the voltage for the MMC1 I/O group
  [8] MAIN_GEN — Indicates the voltage for the General I/O group
  [2] MCU_RGMII — Indicates the voltage for the MCU CPSW2G RGMII I/O group
  [1] MCU_FLASH — Indicates the voltage for the MCU Flash I/O group
  [0] MCU_GEN — Indicates the voltage for the MCU General I/O group
0x18104 CTRLMMR_WKUP_MAIN_POR_TO_CTRL (reset mask 0xFFFFFFF8) — Indicates the MAIN PORz timeout period.
  [2:0] TIMEOUT_PER rw — MAIN PORz hardware timeout period. 0h - Immediate 1h - 100 microsec 2h - 200 microsec 3h - 300 microsec 4h - 400 microsec 5h - 500 microsec
0x18108 CTRLMMR_WKUP_MAIN_PRG_CTRL reset 0x53535353 — Configures the MAIN domain PRG controller.
  [15] POK_EN_SEL rw — Select POK enable source
  [14] POK_VDDR_CORE_OV_EN rw — Enable VDDR_CORE overvoltage POK detection
  [12] POK_VMON_EXT_OV_EN rw — Enable VMON_EXT overvoltage POK detection
  [9] POK_VDD_CPU_OV_EN rw — Enable VDD_CORE overvoltage POK detection
  [8] POK_VDD_CORE_OV_EN rw — Enable VDD_CORE overvoltage POK detection
  [6] POK_VDDR_CORE_UV_EN rw — Enable VDDR_CORE undervoltage POK detection
  [4] POK_VMON_EXT_UV_EN rw — Enable VMON_EXT undervoltage POK detection
  [1] POK_VDD_CPU_UV_EN rw — Enable VDD_CORE undervoltage POK detection
  [0] POK_VDD_CORE_UV_EN rw — Enable VDD_CORE undervoltage POK detection
0x1810C CTRLMMR_WKUP_MAIN_PRG_STAT (reset mask 0xFFFFACAC) — Provides MAIN domain PRG controller status.
  [31] POK_CLR rw — When set, resets pgood sticky bits for VDD_CORE, VDD_CPU, VMON_EXT, and CDDR_CORE voltage POK detection.
  [14] POK_VDDR_CORE_OV ro — VDDR_CORE overvoltage POK
  [12] POK_VMON_EXT_OV ro — VMON_EXT overvoltage POK
  [9] POK_VDD_CPU_OV ro — VDD_CPU overvoltage POK
  [8] POK_VDD_CORE_OV ro — VDD_CORE overvoltage POK
  [6] POK_VDDR_CORE_UV ro — VDDR_CORE undervoltage POK
  [4] POK_VMON_EXT_UV ro — VMON_EXT undervoltage POK
  [1] POK_VDD_CPU_UV ro — VDD_CPU undervoltage POK
  [0] POK_VDD_CORE_UV ro — VDD_CORE undervoltage POK
0x18110 CTRLMMR_WKUP_POK_VDD_CORE_UV_CTRL reset 0x80000000 (reset mask 0xFFFFFF00) — Controls operation of the VDD_CORE undervoltage POK module.
  fields as CTRLMMR_WKUP_POK_VDDSHV_WKUP_GEN_UV_CTRL
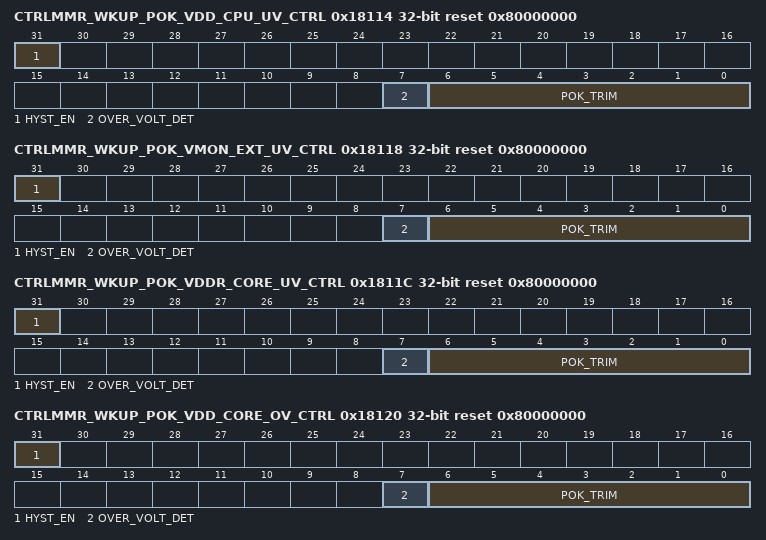
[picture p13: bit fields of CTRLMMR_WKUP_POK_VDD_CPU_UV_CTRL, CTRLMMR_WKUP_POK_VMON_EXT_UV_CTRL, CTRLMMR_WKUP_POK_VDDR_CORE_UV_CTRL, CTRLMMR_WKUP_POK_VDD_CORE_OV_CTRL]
0x18114 CTRLMMR_WKUP_POK_VDD_CPU_UV_CTRL reset 0x80000000 (reset mask 0xFFFFFF00) — Controls operation of the VDD_CPU undervoltage POK module.
  fields as CTRLMMR_WKUP_POK_VDDSHV_WKUP_GEN_UV_CTRL
0x18118 CTRLMMR_WKUP_POK_VMON_EXT_UV_CTRL reset 0x80000000 (reset mask 0xFFFFFF00) — Controls operation of the VMON_EXTC undervoltage POK module.
  fields as CTRLMMR_WKUP_POK_VDDSHV_WKUP_GEN_UV_CTRL
0x1811C CTRLMMR_WKUP_POK_VDDR_CORE_UV_CTRL reset 0x80000000 (reset mask 0xFFFFFF00) — Controls operation of the VDDR_CORE undervoltage POK module.
  fields as CTRLMMR_WKUP_POK_VDDSHV_WKUP_GEN_UV_CTRL
0x18120 CTRLMMR_WKUP_POK_VDD_CORE_OV_CTRL reset 0x80000000 (reset mask 0xFFFFFF00) — Controls operation of the VDD_CORE overvoltage POK module.
  fields as CTRLMMR_WKUP_POK_VDDSHV_WKUP_GEN_UV_CTRL
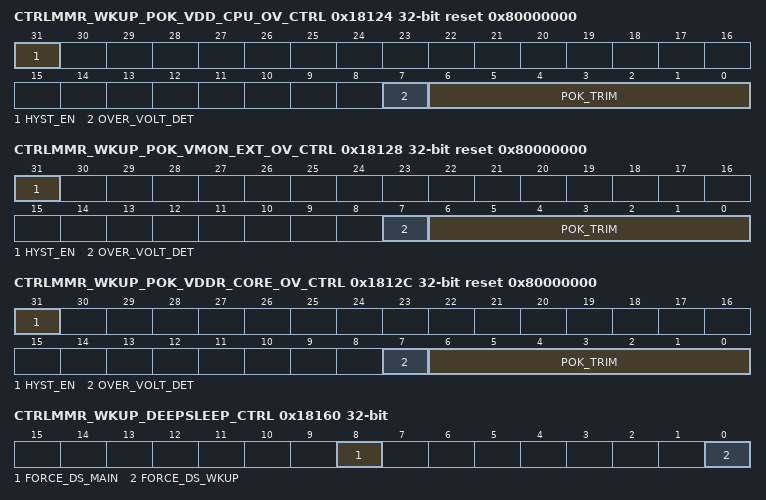
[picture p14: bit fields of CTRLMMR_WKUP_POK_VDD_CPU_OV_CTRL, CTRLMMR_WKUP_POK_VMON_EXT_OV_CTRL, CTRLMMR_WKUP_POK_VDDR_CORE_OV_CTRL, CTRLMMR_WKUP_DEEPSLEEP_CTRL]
0x18124 CTRLMMR_WKUP_POK_VDD_CPU_OV_CTRL reset 0x80000000 (reset mask 0xFFFFFF00) — Controls operation of the VDD_CPU overvoltage POK module.
  fields as CTRLMMR_WKUP_POK_VDDSHV_WKUP_GEN_UV_CTRL
0x18128 CTRLMMR_WKUP_POK_VMON_EXT_OV_CTRL reset 0x80000000 (reset mask 0xFFFFFF00) — Controls operation of the VMON_EXT overvoltage POK module.
  fields as CTRLMMR_WKUP_POK_VDDSHV_WKUP_GEN_UV_CTRL
0x1812C CTRLMMR_WKUP_POK_VDDR_CORE_OV_CTRL reset 0x80000000 (reset mask 0xFFFFFF00) — Controls operation of the VDDR_CORE overvoltage POK module.
  fields as CTRLMMR_WKUP_POK_VDDSHV_WKUP_GEN_UV_CTRL
0x18160 CTRLMMR_WKUP_DEEPSLEEP_CTRL — Used to control IO deepsleep operation.
  [8] FORCE_DS_MAIN rw — Force all MAIN IOs into deepsleep mode when set
  [0] FORCE_DS_WKUP rw — Force all WKUP IOs into deepsleep mode when set
0x18170 CTRLMMR_WKUP_POR_RST_CTRL reset 0xF0000 — Controls MAIN domain power-on reset behavior.
  [24] MAIN_PORZ_DAISYCHAIN_EN rw — MAIN PORz daisy-chain event enable.
  [19:16] SW_MAIN_POR rw — Main Domain software power-on reset. When set to 6h, a power-on is issued to the MAIN voltage domain. (Bits will reset to Fh on reset of the Main Domain)
  [12] MAIN_PORZ_DS_STRETCH rw — DeepSleep mode MAIN PORz stretch.
  [0] POR_RST_ISO_DONE_Z rw — Reset isolation completion (active low). This bit should be cleared only after reset isolation of the MAIN domain is complete.
0x18174 CTRLMMR_WKUP_MAIN_WARM_RST_CTRL reset 0xF0000 — Controls warm reset propagation to the MAIN domain. This allows the DMSC to ensure that the MCU domain is properly isolated before the MAIN domain is reset.
  [19:16] SW_WARMRST rw — Main Domain software warm reset. When set to 6h, a warm reset is issued to the MAIN voltage domain. (Bits will reset to Fh on reset of the Main Domain)
  [0] SOC_WARMRST_ISO_DONE_Z rw — Reset isolation completion (active low). This bit should be cleared only after reset isolation of the MAIN domain is complete.
0x18178 CTRLMMR_WKUP_RST_STAT ro (reset mask 0xFFFEFFFE) — Shows the reset status.
  [16] MCU_RST_DONE — Indicates MCU domain reset status.
  [0] MAIN_RST_DONE — Indicates MAIN domain Warm reset status.
0x1817C CTRLMMR_WKUP_MCU_WARM_RST_CTRL reset 0xF0000 — Controls warm reset propagation to the MCU domain. This allows the DMSC to ensure that the WKUP domain is properly isolated before the MCU domain is reset.
  [19:16] SW_WARMRST rw — Chip software warm reset. When set to 6h, a warm reset is issued to the device (all voltage domains). (Bits will reset to Fh on reset completion.)
0x18180 CTRLMMR_WKUP_VDD_CPU_GLDTC_CTRL (reset mask 0xFFF8C0C0) — Controls the voltage glitch detector circuit monitoring the VDD_CPU voltage domain.
  [31] PWDB rw — Power down - active low.
  [30] RSTB rw — Reset - active low. To ensure proper operation, rstb must not be de-asserted for at least 100 ns after power-up (pwdb de-asserted). Additionally, rstb must be toggled low at least 200 ns after any change in threshold or low-pass filter settings to prevent abnormal trigger events.
  [18:16] LP_FILTER_SEL rw — Selects the glitch detect low-pass filter bandwidth 0h - 150 kHz 1h - 125 kHz 2h - 100 kHz 3h - 80 kHz 4h - 60 kHz 5h - 45 kHz 6h - 30 kHz 7h - 15 kHz
  [13:8] THRESH_HI_SEL rw — Selects the high voltage glitch threshold as a percentage of the monitored voltage 0h - 93.5% of VDD 1h - 94.0% of VDD 2h - 94.5% of VDD 3h - 95.0% of VDD 4h - 95.5% of VDD 5h - 96.0% of VDD 6h - 96.5% of VDD 7h - 97.0% of VDD 8h - 97.5% of VDD 9h - 98.0% of VDD Ah - 98.5% of VDD Bh - 99.0% of VDD Ch - 99.5% of VDD Dh - 100.0% of VDD Eh - 100.5% of VDD Fh - 101.0% of VDD 10h - 101.5% of VDD 11h - 102.0% of VDD 12h - 102.5% of VDD 13h - 103.0% of VDD 14h - 103.5% of VDD 15h - 104.0% of VDD 16h - 104.5% of VDD 17h - 105.0% of VDD 18h - 105.5% of VDD 19h - 106.0% of VDD 1Ah - 106.5% of VDD 1Bh - 107.0% of VDD 1Ch - 107.5% of VDD 1Dh - 108.0% of VDD 1Eh - 108.5% of VDD 1Fh - 109.0% of VDD20h - 109.5% of VDD 21h - 110.0% of VDD 22h - 111.0% of VDD 23h - 112.0% of VDD 24h - 113.0% of VDD 25h - 114.0% of VDD 26h - 115.0% of VDD 27h - 116.0% of VDD 28h - 117.0% of VDD 29h - 118.0% of VDD 2Ah - 119.0% of VDD 2Bh - 120.0% of VDD 2Ch - 121.0% of VDD 2Dh - 122.0% of VDD 2Eh - 123.0% of VDD 2Fh - 124.0% of VDD 30h - 125.0% of VDD 31h - 126.0% of VDD 32h - 127.0% of VDD 33h - 128.0% of VDD 34h - 129.0% of VDD 35h - 130.0% of VDD 36h - 131.0% of VDD 37h - 132.0% of VDD 38h - 133.0% of VDD 39h - 134.0% of VDD 3Ah - 135.0% of VDD 3Bh - 136.0% of VDD 3Ch - 137.0% of VDD 3Dh - 138.0% of VDD 3Eh - 139.0% of VDD 3Fh - 140.0% of VDD .
  [5:0] THRESH_LO_SEL rw — Selects the low voltage glitch threshold as a percentage of the monitored voltage 0h - 106.5% of VDD 1h - 106.0% of VDD 2h - 105.5% of VDD 3h - 105.0% of VDD 4h - 104.5% of VDD 5h - 104.0% of VDD 6h - 103.5% of VDD 7h - 103.0% of VDD 8h - 102.5% of VDD 9h - 102.0% of VDD Ah - 101.5% of VDD Bh - 101.0% of VDD Ch - 100.5% of VDD Dh - 100.0% of VDD Eh - 99.5% of VDD Fh - 99.0% of VDD 10h - 98.5% of VDD 11h - 98.0% of VDD 12h - 97.5% of VDD 13h - 97.0% of VDD 14h - 96.5% of VDD 15h - 96.0% of VDD 16h - 95.5% of VDD 17h - 95.0% of VDD 18h - 94.5% of VDD 19h - 94.0% of VDD 1Ah - 93.5% of VDD 1Bh - 93.0% of VDD 1Ch - 92.5% of VDD 1Dh - 92.0% of VDD 1Eh - 91.5% of VDD 1Fh - 91.0% of VDD20h - 90.5% of VDD 21h - 90.0% of VDD 22h - 89.0% of VDD 23h - 88.0% of VDD 24h - 87.0% of VDD 25h - 86.0% of VDD 26h - 85.0% of VDD 27h - 84.0% of VDD 28h - 83.0% of VDD 29h - 82.0% of VDD 2Ah - 81.0% of VDD 2Bh - 80.0% of VDD 2Ch - 79.0% of VDD 2Dh - 78.0% of VDD 2Eh - 77.0% of VDD 2Fh - 76.0% of VDD 30h - 75.0% of VDD 31h - 74.0% of VDD 32h - 73.0% of VDD 33h - 72.0% of VDD 34h - 71.0% of VDD 35h - 70.0% of VDD 36h - 69.0% of VDD 37h - 68.0% of VDD 38h - 67.0% of VDD 39h - 66.0% of VDD 3Ah - 65.0% of VDD 3Bh - 64.0% of VDD 3Ch - 63.0% of VDD 3Dh - 62.0% of VDD 3Eh - 61.0% of VDD 3Fh - 60.0% of VDD .
0x18190 CTRLMMR_WKUP_VDD_CORE_GLDTC_CTRL (reset mask 0xFFF8C0C0) — Controls the voltage glitch detector circuit monitoring the VDD_CORE voltage domain.
  fields as CTRLMMR_WKUP_VDD_CPU_GLDTC_CTRL
0x18194 CTRLMMR_WKUP_VDDR_CPU_GLDTC_CTRL (reset mask 0xFFF8C0C0) — Controls the voltage glitch detector circuit monitoring the VDDR_CORE voltage domain.
  fields as CTRLMMR_WKUP_VDD_CPU_GLDTC_CTRL
0x18198 CTRLMMR_WKUP_VDDR_CORE_GLDTC_CTRL (reset mask 0xFFF8C0C0) — Controls the voltage glitch detector circuit monitoring the VDDR_CPU voltage domain.
  fields as CTRLMMR_WKUP_VDD_CPU_GLDTC_CTRL
0x181A0 CTRLMMR_WKUP_VDD_CPU_GLDTC_STAT ro (reset mask 0xFFFFFEFE) — Shows the status of the voltage glitch detector circuit monitoring the VDD_CPU voltage domain.
  [8] THRESH_HI_FLAG — High voltage flag. This flag is cleared by clearing the VDD_CPU_GLDTC_CTRL_rstb bit.
  [0] THRESH_LOW_FLAG — Low voltage flag. This flag is cleared by clearing the VDD_CPU_GLDTC_CTRL_rstb bit.
0x181B0 CTRLMMR_WKUP_VDD_CORE_GLDTC_STAT ro (reset mask 0xFFFFFEFE) — Shows the status of the voltage glitch detector circuit monitoring the VDD_CORE voltage domain.
  [8] THRESH_HI_FLAG — High voltage flag. This flag is cleared by clearing the VDD_CORE_GLDTC_CTRL_rstb bit.
  [0] THRESH_LOW_FLAG — Low voltage flag. This flag is cleared by clearing the VDD_CORE_GLDTC_CTRL_rstb bit.
0x181B4 CTRLMMR_WKUP_VDDR_CPU_GLDTC_STAT ro (reset mask 0xFFFFFEFE) — Shows the status of the voltage glitch detector circuit monitoring the VDDR_CPU voltage domain.
  [8] THRESH_HI_FLAG — High voltage flag. This flag is cleared by clearing the VDDR_CPU_GLDTC_CTRL_rstb bit.
  [0] THRESH_LOW_FLAG — Low voltage flag. This flag is cleared by clearing the VDDR_CPU_GLDTC_CTRL_rstb bit.
0x181B8 CTRLMMR_WKUP_VDDR_CORE_GLDTC_STAT ro (reset mask 0xFFFFFEFE) — Shows the status of the voltage glitch detector circuit monitoring the VDDR_CORE voltage domain.
  [8] THRESH_HI_FLAG — High voltage flag. This flag is cleared by clearing the VDDR_CORE_GLDTC_CTRL_rstb bit.
  [0] THRESH_LOW_FLAG — Low voltage flag. This flag is cleared by clearing the VDDR_CORE_GLDTC_CTRL_rstb bit.
0x181C0 CTRLMMR_WKUP_VDD_MCU_GLDTC_CTRL (reset mask 0xFFF8C0C0) — Controls the voltage glitch detector circuit monitoring the VDD_MCU voltage domain.
  fields as CTRLMMR_WKUP_VDD_CPU_GLDTC_CTRL
0x181C4 CTRLMMR_WKUP_VDDR_MCU_GLDTC_CTRL (reset mask 0xFFF8C0C0) — Controls the voltage glitch detector circuit monitoring the VDDR_MCU voltage domain.
  fields as CTRLMMR_WKUP_VDD_CPU_GLDTC_CTRL
0x181D0 CTRLMMR_WKUP_VDD_MCU_GLDTC_STAT ro (reset mask 0xFFFFFEFE) — Shows the status of the voltage glitch detector circuit monitoring the VDD_MCU voltage domain.
  [8] THRESH_HI_FLAG — High voltage flag. This flag is cleared by clearing the VDD_MCU_GLDTC_CTRL_rstb bit.
  [0] THRESH_LOW_FLAG — Low voltage flag. This flag is cleared by clearing the VDD_MCU_GLDTC_CTRL_rstb bit.
0x181D4 CTRLMMR_WKUP_VDDR_MCU_GLDTC_STAT ro (reset mask 0xFFFFFEFE) — Shows the status of the voltage glitch detector circuit monitoring the VDDR_MCU voltage domain.
  [8] THRESH_HI_FLAG — High voltage flag. This flag is cleared by clearing the VDDR_MCU_GLDTC_CTRL_rstb bit.
  [0] THRESH_LOW_FLAG — Low voltage flag. This flag is cleared by clearing the VDDR_MCU_GLDTC_CTRL_rstb bit.
0x19008 CTRLMMR_WKUP_LOCK6_KICK0 — Lower 32-bits of Partition6 write lock key. This register must be written with the designated key value followed by a write to with its key value before write-protected Partition 6 registers can be written.
  [31:1] KEY rw — Write the kick0 unlock value followed by the kick1 unlock value to unlock the write-protected Partition6 registers
  [0] UNLOCKED ro — Unlock status.
0x1900C CTRLMMR_WKUP_LOCK6_KICK1 rw — Upper 32-bits of Partition 6 write lock key. This register must be written with the designated key value after a write to with its key value before write-protected Partition 6 registers can be written.
  [31:0] KEY — Write the kick1 unlock value after the kick0 unlock value to unlock the write-protected Partition6 registers
0x1C000 CTRLMMR_WKUP_PADCONFIG0 reset 0x8214007 — Register to control pin configuration and muxing.
  [31] LOCK rw
  [30] WKUP_EVT ro — Wakeup event status
  [29] WKUP_EN rw — Wakeup enable
  [28] DS_PULLTYPE_SEL rw — Deep Sleep pull-up/down selection
  [27] DS_PULLUD_EN rw — Deep Sleep pull-up/down enable (active low)
  [26] DSOUT_VAL rw — Deep Sleep output value
  [25] DSOUT_DIS rw — Deep Sleep output enable
  [24] DS_EN rw — Deep Sleep override control
  [23] ISO_BYP rw — Isolation Bypass
  [22] ISO_OVR rw — Isolation Override
  [21] TX_DIS rw — Driver Disable
  [20:19] DRV_STR rw — Drive Strentgth Control . Selectes the drive strength value for LVCMOS pins. (Does not apply to other pin types)
  [18] RXACTIVE rw — Input enable for the Pad
  [17] PULLTYPESEL rw — Pad Pullup / Pulldown type selection
  [16] PULLUDEN rw — Pad Pullup / Pulldown enable. This is an active low signal.
  [15] FORCE_DS_EN rw — Enable pad Deep Sleep controls by overriding DMSC gating
  [14] ST_EN rw — Receiver Schmitt Trigger enable
  [13:11] DEBOUNCE_SEL rw — Selects the debouce period for the pad.
  [5:4] VGPIO_SEL rw — Virtual WKUP_GPIO instance select. 0h - Implement GPIO in GPIO_WKUP_0 instance 1h - Implement GPIO in GPIO_WKUP_1 instance
  [3:0] MUXMODE rw — Pad functional signal mux selection 0h - Mux Mode 0 1h - Mux Mode 1 2h - Mux Mode 2 3h - Mux Mode 3 4h - Mux Mode 4 5h - Mux Mode 5 6h - Mux Mode 6 7h - Mux Mode 7 Fh - Mux Mode 15
0x1C004 CTRLMMR_WKUP_PADCONFIG1 reset 0x8254007 — Register to control pin configuration and muxing.
  fields as CTRLMMR_WKUP_PADCONFIG0
{0x1C000+4i} CTRLMMR_WKUP_PADCONFIG{i} reset 0x8214007 (i=2..13) — Register to control pin configuration and muxing.
  fields as CTRLMMR_WKUP_PADCONFIG0
0x1C038 CTRLMMR_WKUP_PADCONFIG14 reset 0x8254007 — Register to control pin configuration and muxing.
  fields as CTRLMMR_WKUP_PADCONFIG0
{0x1C000+4i} CTRLMMR_WKUP_PADCONFIG{i} reset 0x8214007 (i=15..35) — Register to control pin configuration and muxing.
  fields as CTRLMMR_WKUP_PADCONFIG0
{0x1C000+4i} CTRLMMR_WKUP_PADCONFIG{i} reset 0x8254007 (i=36..38) — Register to control pin configuration and muxing.
  fields as CTRLMMR_WKUP_PADCONFIG0
{0x1C000+4i} CTRLMMR_WKUP_PADCONFIG{i} reset 0x8214007 (i=39..43) — Register to control pin configuration and muxing.
  fields as CTRLMMR_WKUP_PADCONFIG0
{0x1C000+4i} CTRLMMR_WKUP_PADCONFIG{i} reset 0x8254007 (i=44..46) — Register to control pin configuration and muxing.
  fields as CTRLMMR_WKUP_PADCONFIG0
{0x1C000+4i} CTRLMMR_WKUP_PADCONFIG{i} reset 0x8214007 (i=47..55) — Register to control pin configuration and muxing.
  fields as CTRLMMR_WKUP_PADCONFIG0
{0x1C000+4i} CTRLMMR_WKUP_PADCONFIG{i} reset 0x8254007 (i=56..59) — Register to control pin configuration and muxing.
  fields as CTRLMMR_WKUP_PADCONFIG0
0x1C0F0 CTRLMMR_WKUP_PADCONFIG60 reset 0x8214007 — Register to control pin configuration and muxing.
  fields as CTRLMMR_WKUP_PADCONFIG0
0x1C0F4 CTRLMMR_WKUP_PADCONFIG61 reset 0x8214007 — Register to control pin configuration and muxing.
  fields as CTRLMMR_WKUP_PADCONFIG0
{0x1C000+4i} CTRLMMR_WKUP_PADCONFIG{i} reset 0x44000 (i=62..65) — Register to control pin configuration and muxing.
  [31] LOCK rw
  [30] WKUP_EVT ro — Wakeup event status
  [29] WKUP_EN rw — Wakeup enable
  [26] DSOUT_VAL rw — Deep Sleep output value
  [25] DSOUT_DIS rw — Deep Sleep output enable
  [24] DS_EN rw — Deep Sleep override control
  [23] ISO_BYP rw — Isolation Bypass
  [22] ISO_OVR rw — Isolation Override
  [21] TX_DIS rw — Driver Disable
  [18] RXACTIVE rw — Input enable for the Pad
  [15] FORCE_DS_EN rw — Enable pad Deep Sleep controls by overriding DMSC gating
  [14] ST_EN rw — Receiver Schmitt Trigger enable
  [13:11] DEBOUNCE_SEL rw — Selects the debouce period for the pad.
  [5:4] VGPIO_SEL rw — Virtual WKUP_GPIO instance select. 0h - Implement GPIO in GPIO_WKUP_0 instance 1h - Implement GPIO in GPIO_WKUP_1 instance
  [3:0] MUXMODE rw — Pad functional signal mux selection 0h - Mux Mode 0 1h - Mux Mode 1 2h - Mux Mode 2 3h - Mux Mode 3 4h - Mux Mode 4 5h - Mux Mode 5 6h - Mux Mode 6 7h - Mux Mode 7 Fh - Mux Mode 15
0x1C108 CTRLMMR_WKUP_PADCONFIG66 reset 0x8014007 — Register to control pin configuration and muxing.
  fields as CTRLMMR_WKUP_PADCONFIG0
0x1C10C CTRLMMR_WKUP_PADCONFIG67 reset 0x8014000 — Register to control pin configuration and muxing.
  fields as CTRLMMR_WKUP_PADCONFIG0
0x1C110 CTRLMMR_WKUP_PADCONFIG68 reset 0x44000 — Register to control pin configuration and muxing.
  fields as CTRLMMR_WKUP_PADCONFIG0
0x1C114 CTRLMMR_WKUP_PADCONFIG69 reset 0x10264000 — Register to control pin configuration and muxing.
  fields as CTRLMMR_WKUP_PADCONFIG0
0x1C118 CTRLMMR_WKUP_PADCONFIG70 reset 0x8014000 — Register to control pin configuration and muxing.
  fields as CTRLMMR_WKUP_PADCONFIG0
0x1C11C CTRLMMR_WKUP_PADCONFIG71 reset 0x8014000 — Register to control pin configuration and muxing.
  fields as CTRLMMR_WKUP_PADCONFIG0
0x1C120 CTRLMMR_WKUP_PADCONFIG72 reset 0x10264000 — Register to control pin configuration and muxing.
  fields as CTRLMMR_WKUP_PADCONFIG0
0x1C124 CTRLMMR_WKUP_PADCONFIG73 reset 0x244000 — Register to control pin configuration and muxing.
  fields as CTRLMMR_WKUP_PADCONFIG0
0x1C128 CTRLMMR_WKUP_PADCONFIG74 reset 0x10264000 — Register to control pin configuration and muxing.
  fields as CTRLMMR_WKUP_PADCONFIG0
0x1C12C CTRLMMR_WKUP_PADCONFIG75 reset 0x10264000 — Register to control pin configuration and muxing.
  fields as CTRLMMR_WKUP_PADCONFIG0
{0x1C000+4i} CTRLMMR_WKUP_PADCONFIG{i} (i=76..91) — Register to control pin configuration and muxing.
  [31] LOCK rw
  [13:11] DEBOUNCE_SEL rw — Selects the debouce period for the pad.
  [5:4] VGPIO_SEL rw — Virtual WKUP_GPIO instance select. 0h - Implement GPIO in GPIO_WKUP_0 instance 1h - Implement GPIO in GPIO_WKUP_1 instance
0x1C170 CTRLMMR_WKUP_PADCONFIG92 reset 0x10264000 — Register to control pin configuration and muxing.
  fields as CTRLMMR_WKUP_PADCONFIG0
0x1C174 CTRLMMR_WKUP_PADCONFIG93 reset 0x8014000 — Register to control pin configuration and muxing.
  fields as CTRLMMR_WKUP_PADCONFIG0
0x1D008 CTRLMMR_WKUP_LOCK7_KICK0 — Lower 32-bits of Partition7 write lock key. This register must be written with the designated key value followed by a write to with its key value before write-protected Partition 7 registers can be written.
  [31:1] KEY rw — Write the kick0 unlock value followed by the kick1 unlock value to unlock the write-protected Partition7 registers
  [0] UNLOCKED ro — Unlock status.
0x1D00C CTRLMMR_WKUP_LOCK7_KICK1 rw — Upper 32-bits of Partition 7 write lock key. This register must be written with the designated key value after a write to with its key value before write-protected Partition 7 registers can be written.
  [31:0] KEY — Write the kick1 unlock value after the kick0 unlock value to unlock the write-protected Partition7 registers
